# MLDR187 register map
File version: 1.3
CPU: MLDR178, little endian
Registers are 32-bit, read-write, no defined reset value unless marked. A register's access mark holds for its fields unless they carry their own. Offsets are from the block's base; [hi:lo] are bit positions; {n}, {i} and the like mark numbered series.

## CRC — CRC description
Base 0x40098000
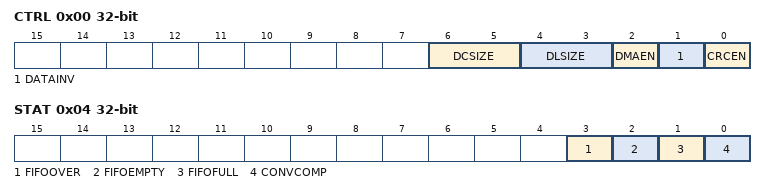
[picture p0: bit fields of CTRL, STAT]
0x00 CTRL — CTRL description
  [6:5] DCSIZE — DCSIZE description
  [4:3] DLSIZE — DLSIZE description
  [2] DMAEN — DMAEN description
  [1] DATAINV — DATAINV description
  [0] CRCEN — CRCEN description
0x04 STAT — STAT description
  [3] FIFOOVER — FIFOOVER description
  [2] FIFOEMPTY — FIFOEMPTY description
  [1] FIFOFULL — FIFOFULL description
  [0] CONVCOMP — CONVCOMP description
0x08 DATAI wo — DATAI description
  [31:0] DATA_IN — DATA_IN description
0x0C VAL — VAL description
  [15:0] CRCOUT — CRCOUT description
0x10 POL — POL description
  [16:0] CRC_POL — CRC_POL description

## EEPROM_CNTRL — EEPROM_CNTRL description
Base 0x40018000
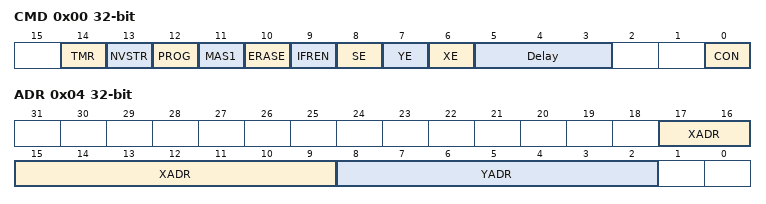
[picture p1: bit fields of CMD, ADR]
0x00 CMD — Registr upravlenija
  [14] TMR — Bit perevoda pamjat' v testovyj rezhim
  [13] NVSTR — Operacii zapisi ili stiranija
  [12] PROG — Bit programirovanija pamjati pri dostupe v pamjat'
  [11] MAS1 — Bit stiranija pamjati pri dostupe v pamjat'
  [10] ERASE — Bit stiranija pamjati pri dostupe v pamjat'
  [9] IFREN — Bit vybora tipa pamjati pri dostupe v pamjat'
  [8] SE — Bit razreshenija mladshej chasti adresa pri dostupe v pamjat' so storony registrov.
  [7] YE — Bit razreshenija starshej chasti adresa pri dostupe v pamjat' so storony registrov.
  [6] XE — Bit razreshenija dostupa k bankam pamjati
  [5:3] Delay — Zaderzhka pamjati programm pri chtenii v ciklah (v rabochem rezhime)
  [0] CON — Perekljuchenie kontrollera pamjati EEPROM na registrovoe upravlenie
0x04 ADR — ADR description
  [17:9] XADR — XADR[8:0] = page[5:0], row[2:0]
  [8:2] YADR — YADR[6:0] = col[6:0]
0x08 DI — Dannye dlja zapisi v EERPOM
0x0C DO — Dannye, schitannye iz EERPOM
0x10 KEY — 0x8AAA5551

## ADC — ADC description
Base 0x40040000
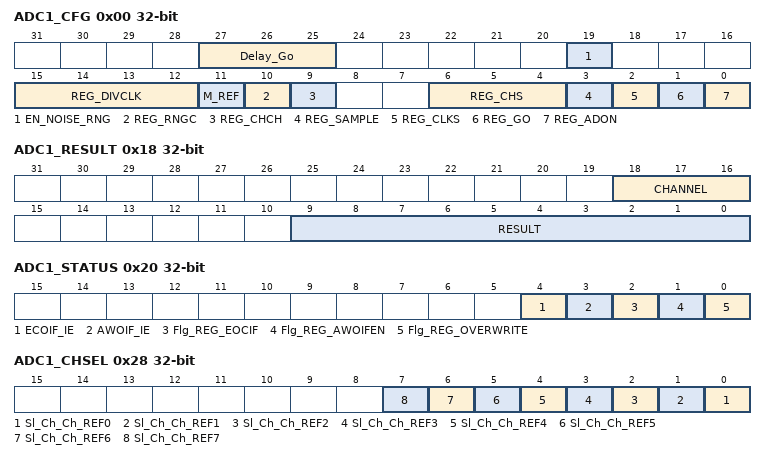
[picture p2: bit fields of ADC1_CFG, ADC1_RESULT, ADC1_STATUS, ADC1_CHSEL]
0x00 ADC1_CFG — ADC1_CFG description
  [27:25] Delay_Go — Delay_Go description
  [19] EN_NOISE_RNG — EN_NOISE_RNG description
  [15:12] REG_DIVCLK — REG_DIVCLK description
  [11] M_REF — M_REF description
  [10] REG_RNGC — REG_RNGC description
  [9] REG_CHCH — REG_CHCH description
  [6:4] REG_CHS — REG_CHS description
  [3] REG_SAMPLE — REG_SAMPLE description
  [2] REG_CLKS — REG_CLKS description
  [1] REG_GO — REG_GO description
  [0] REG_ADON — REG_ADON description
0x08 ADC1_H_LEVEL — ADC1_H_LEVEL description
  [9:0] REG_H_LEVEL — REG_H_LEVEL description
0x10 ADC1_L_LEVEL — ADC1_L_LEVEL description
  [9:0] REG_L_LEVEL — REG_L_LEVEL description
0x18 ADC1_RESULT — ADC1_RESULT description
  [18:16] CHANNEL — CHANNEL description
  [9:0] RESULT — RESULT description
0x20 ADC1_STATUS — ADC1_STATUS description
  [4] ECOIF_IE — ECOIF_IE description
  [3] AWOIF_IE — AWOIF_IE description
  [2] Flg_REG_EOCIF — Flg_REG_EOCIF description
  [1] Flg_REG_AWOIFEN — Flg_REG_AWOIFEN description
  [0] Flg_REG_OVERWRITE — Flg_REG_OVERWRITE description
0x28 ADC1_CHSEL — ADC1_CHSEL description
  [n] Sl_Ch_Ch_REF{n} (n=0..7) — Sl_Ch_Ch_REF{n} description
0x30 ADC1_TRIM — ADC1_TRIM description
  [5:1] BG_TRIM — BG_TRIM description

## WWDG — WWDG description
Base 0x40048000
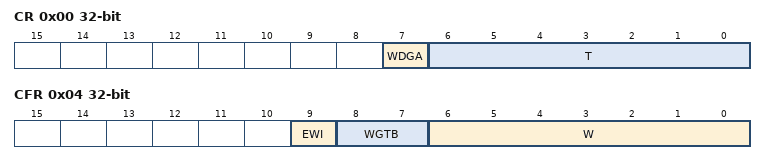
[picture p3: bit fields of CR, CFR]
0x00 CR — CR description
  [7] WDGA — WDGA description
  [6:0] T — T description
0x04 CFR — CFR description
  [9] EWI — EWI description
  [8:7] WGTB — WGTB description
  [6:0] W — W description
0x08 SR — SR description
  [0] EWIF — EWIF description

## IWDG — IWDG description
Base 0x40050000
0x00 KR — KR description
  [15:0] KEY — KEY description
0x04 PR — PR description
  [2:0] PR
0x08 RLR — RLR description
  [11:0] RLR
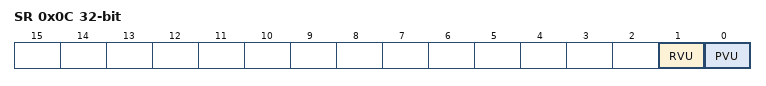
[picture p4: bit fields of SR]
0x0C SR — SR description
  [1] RVU — RVU description
  [0] PVU — PVU description

## ISO7816 — ISO7816 description
Base 0x400C0000
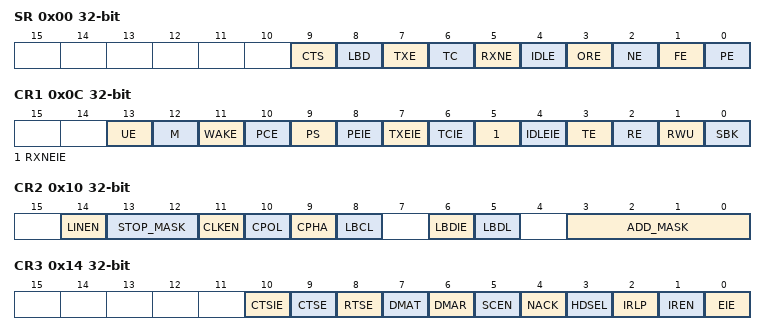
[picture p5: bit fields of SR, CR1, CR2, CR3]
0x00 SR — Status register
  [9] CTS — CTS flag
  [8] LBD — LIN break flag
  [7] TXE — TX empty
  [6] TC — Transmit complete
  [5] RXNE — Read data register not empty
  [4] IDLE — IDLE line detected
  [3] ORE — Overrun error
  [2] NE — Noise error flag
  [1] FE — Frame error
  [0] PE — Parity error
0x04 DR — Data register
0x08 BRR — Baud rate register
0x0C CR1 — Control register 1
  [13] UE — USART Enable
  [12] M — Byte len. 1 - 9;0 - 8
  [11] WAKE — Wake bit
  [10] PCE — Parity control enable
  [9] PS — Parity selection
  [8] PEIE — PE interrupt enable
  [7] TXEIE — TXE interrupt enable
  [6] TCIE — Transmission complete interrupt enable
  [5] RXNEIE — RXNE interrupt enable
  [4] IDLEIE — IDLE interrupt enable
  [3] TE — Transmitter enable
  [2] RE — Receiver enable
  [1] RWU — Receiver wakeup
  [0] SBK — Send break
0x10 CR2 — Control register 2
  [14] LINEN — LIN mode enable
  [13:12] STOP_MASK — Stop bit type mask
  [11] CLKEN — Clock enable
  [10] CPOL — Clock polarity
  [9] CPHA — Clock phase
  [8] LBCL — Last bit clock pulse
  [6] LBDIE — LIN break detection interrupt enable
  [5] LBDL — LIN break detection length
  [3:0] ADD_MASK — Address of the USART node
0x14 CR3 — Control register 3
  [10] CTSIE — CTS interrupt enable
  [9] CTSE — CTS enable
  [8] RTSE — RTS enable
  [7] DMAT — DMA enable transmitter
  [6] DMAR — DMA enable receiver
  [5] SCEN — Smartcard mode enable
  [4] NACK — Smartcard NACK
  [3] HDSEL — Half-duplex selection
  [2] IRLP — IrDA low-power
  [1] IREN — IrDA mode enable
  [0] EIE — Error interrupt enable
0x18 GTPR — Guard time and prescaler register
